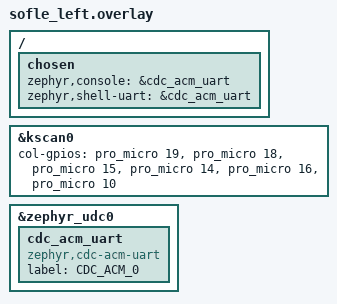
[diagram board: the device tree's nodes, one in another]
/*
 * Copyright (c) 2020 Ryan Cross
 *
 * SPDX-License-Identifier: MIT
 */

#include "sofle.dtsi"

&kscan0 {
    col-gpios
        = <&pro_micro 19 GPIO_ACTIVE_HIGH>
        , <&pro_micro 18 GPIO_ACTIVE_HIGH>
        , <&pro_micro 15 GPIO_ACTIVE_HIGH>
        , <&pro_micro 14 GPIO_ACTIVE_HIGH>
        , <&pro_micro 16 GPIO_ACTIVE_HIGH>
        , <&pro_micro 10 GPIO_ACTIVE_HIGH>
        ;
};

/ {
    chosen {
        zephyr,console = &cdc_acm_uart;
        zephyr,shell-uart = &cdc_acm_uart;
    };
};

&zephyr_udc0 {
    cdc_acm_uart: cdc_acm_uart {
        compatible = "zephyr,cdc-acm-uart";
        label = "CDC_ACM_0";
    };
};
